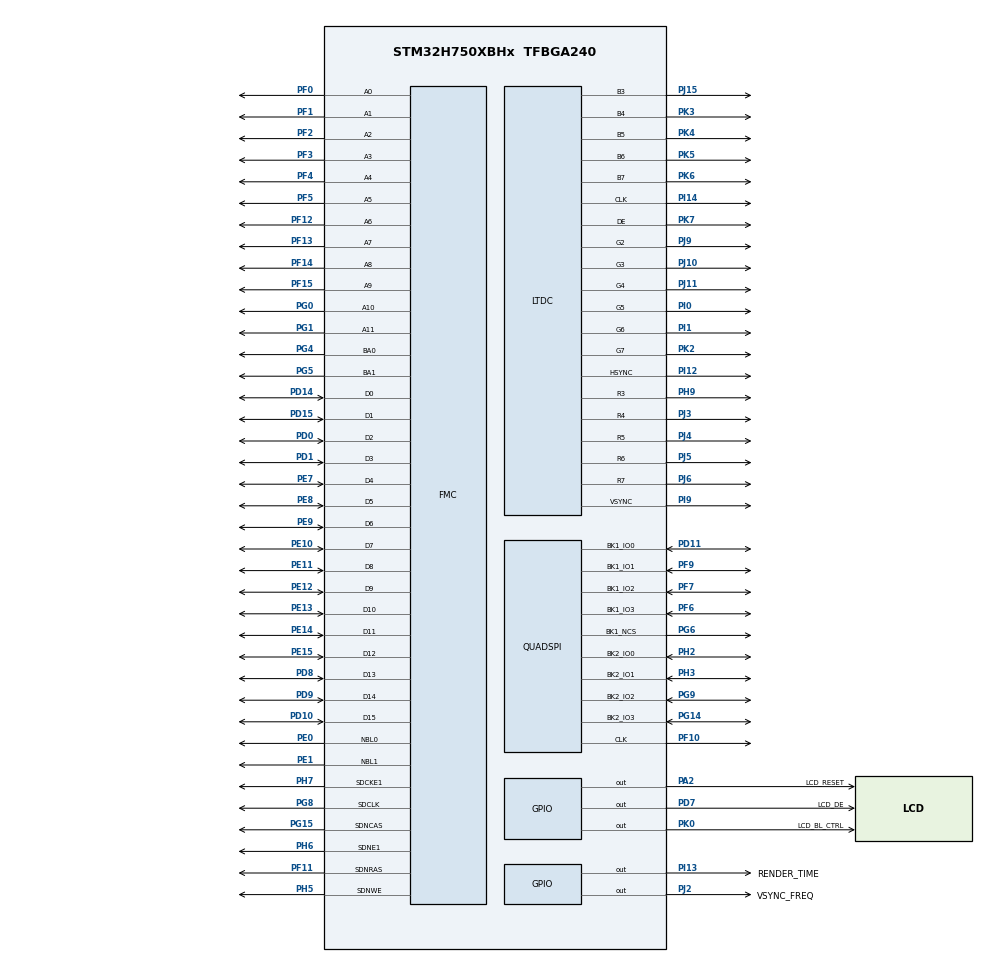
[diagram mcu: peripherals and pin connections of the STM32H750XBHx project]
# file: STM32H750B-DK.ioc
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SH.FMC_D7_DA7.0=FMC_D7,sd-16b-d2
PK5.Signal=LTDC_B6
VP_SYS_VS_tim6.Mode=TIM6
FMC.RCDDelay2=2
PJ9.Mode=RGB565
FMC.SDClockPeriod2=FMC_SDRAM_CLOCK_PERIOD_2
SH.FMC_A0.0=FMC_A0,12b-sda2
QUADSPI.ClockPrescaler=3
CORTEX_M7.BaseAddress-Cortex_Memory_Protection_Unit_Region3_Settings=0xD0000000
NVIC.TIM6_DAC_IRQn=true\:0\:0\:false\:false\:true\:false\:false\:true
PG8.Signal=FMC_SDCLK
PG4.Signal=FMC_A14_BA0
PJ10.GPIO_Speed=GPIO_SPEED_FREQ_HIGH
PG0.Signal=FMC_A10
FMC.LoadToActiveDelay2=2
CORTEX_M7.AccessPermission-Cortex_Memory_Protection_Unit_Region2_Settings=MPU_REGION_FULL_ACCESS
PJ8.GPIO_Speed=GPIO_SPEED_FREQ_HIGH
CORTEX_M7.IsShareable-Cortex_Memory_Protection_Unit_Region4_Settings=MPU_ACCESS_NOT_SHAREABLE
SH.FMC_D5_DA5.0=FMC_D5,sd-16b-d2
PG6.Mode=Enable Chip Select 1 for both banks
RCC.SYSCLKSource=RCC_SYSCLKSOURCE_PLLCLK
PJ10.Signal=LTDC_G3
SH.FMC_A15_BA1.0=FMC_BA1,FourSdramBanks2
SH.FMC_D9_DA9.0=FMC_D9,sd-16b-d2
CORTEX_M7.Enable-Cortex_Memory_Protection_Unit_Region0_Settings=MPU_REGION_ENABLE
CORTEX_M7.IsBufferable-Cortex_Memory_Protection_Unit_Region1_Settings=MPU_ACCESS_NOT_BUFFERABLE
PH5.Signal=FMC_SDNWE
PF7.Signal=QUADSPI_BK1_IO2
NVIC.DMA2D_IRQn=true\:5\:0\:true\:false\:true\:true\:true\:true
PI13.PinState=GPIO_PIN_SET
SH.FMC_SDNWE.0=FMC_SDNWE,12b-sda2
PH9.Signal=LTDC_R3
SH.FMC_D11_DA11.0=FMC_D11,sd-16b-d2
PJ5.Mode=RGB565
PD0.Signal=FMC_D2_DA2
PD8.Signal=FMC_D13_DA13
PE1.Signal=FMC_NBL1
QUADSPI.FlashSize=26
RCC.DIVM3=5
RCC.DIVM1=5
PG14.Mode=Dual_Bank
FMC.SelfRefreshTime2=4
LTDC.PixelFormat_L0=LTDC_PIXEL_FORMAT_RGB565
PK7.Mode=RGB565
PE9.Signal=FMC_D6_DA6
SH.FMC_A2.0=FMC_A2,12b-sda2
FREERTOS.HEAP_NUMBER=4
STMicroelectronics.X-CUBE-TOUCHGFX.4.16.1.tgfx_display_interface=disp_ltdc
PJ1.GPIO_Speed=GPIO_SPEED_FREQ_HIGH
SH.FMC_D1_DA1.0=FMC_D1,sd-16b-d2
PF3.Signal=FMC_A3
CORTEX_M7.Size-Cortex_Memory_Protection_Unit_Region4_Settings=MPU_REGION_SIZE_32MB
PE10.Signal=FMC_D7_DA7
LTDC.HSync=40
CORTEX_M7.DisableExec-Cortex_Memory_Protection_Unit_Region1_Settings=MPU_INSTRUCTION_ACCESS_DISABLE
PJ14.Signal=LTDC_B2
Mcu.Package=TFBGA240
NVIC.TimeBase=TIM6_DAC_IRQn
PH3.GPIO_Speed=GPIO_SPEED_FREQ_VERY_HIGH
RCC.PLL3FRACN=0
PK6.GPIO_Speed=GPIO_SPEED_FREQ_HIGH
STMicroelectronics.X-CUBE-TOUCHGFX.4.16.1.ApplicationCcGraphicsJjApplication=TouchGFXOoGenerator
PJ4.Signal=LTDC_R5
NVIC.TimeBaseIP=TIM6
CORTEX_M7.BaseAddress-Cortex_Memory_Protection_Unit_Region4_Settings=0xD0000000
FMC.WriteRecoveryTime2=5
SH.FMC_A1.0=FMC_A1,12b-sda2
PI12.GPIO_Speed=GPIO_SPEED_FREQ_HIGH
PH2.Signal=QUADSPI_BK2_IO0
PJ3.GPIO_Speed=GPIO_SPEED_FREQ_HIGH
SH.FMC_SDCLK.0=FMC_SDCLK,12b-sda2
LTDC.VSync=9
RCC.APB4Freq_Value=100000000
PF14.Signal=FMC_A8
CORTEX_M7.Enable-Cortex_Memory_Protection_Unit_Region1_Settings=MPU_REGION_ENABLE
VP_DMA2D_VS_DMA2D.Mode=DMA2D_Activate
FMC.RowCycleDelay2=7
PF10.Mode=Dual_Bank
FMC.ColumnBitsNumber2=FMC_SDRAM_COLUMN_BITS_NUM_8
PH0-OSC_IN\ (PH0).Mode=HSE-External-Oscillator
SH.FMC_D3_DA3.0=FMC_D3,sd-16b-d2
PD15.Signal=FMC_D1_DA1
CORTEX_M7.IsBufferable-Cortex_Memory_Protection_Unit_Region0_Settings=MPU_ACCESS_BUFFERABLE
PJ5.GPIO_Speed=GPIO_SPEED_FREQ_HIGH
PG6.GPIO_Speed=GPIO_SPEED_FREQ_VERY_HIGH
PI14.GPIO_Speed=GPIO_SPEED_FREQ_HIGH
VP_STMicroelectronics.X-CUBE-TOUCHGFX_VS_GraphicsJjApplication_4.16.1.Mode=GraphicsJjApplication
PK4.Signal=LTDC_B5
SH.FMC_A4.0=FMC_A4,12b-sda2
RCC.DIVQ1=4
FREERTOS.Tasks01=GUITask,24,8192,TouchGFX_Task,As weak,NULL,Dynamic,NULL,NULL
STMicroelectronics.X-CUBE-TOUCHGFX.4.16.1.tgfx_address1=0xD0000000
STMicroelectronics.X-CUBE-TOUCHGFX.4.16.1.tgfx_address2=0xD003FC00
PG5.Signal=FMC_A15_BA1
PG9.Signal=QUADSPI_BK2_IO2
SH.FMC_D10_DA10.0=FMC_D10,sd-16b-d2
CORTEX_M7.IsBufferable-Cortex_Memory_Protection_Unit_Region2_Settings=MPU_ACCESS_BUFFERABLE
CORTEX_M7.IsCacheable-Cortex_Memory_Protection_Unit_Region0_Settings=MPU_ACCESS_CACHEABLE
CORTEX_M7.Enable-Cortex_Memory_Protection_Unit_Region4_Settings=MPU_REGION_ENABLE
PG9.Mode=Dual_Bank
PD7.Signal=GPIO_Output
PD1.Signal=FMC_D3_DA3
PI12.Signal=LTDC_HSYNC
PJ11.Signal=LTDC_G4
LTDC.ImageWidth_L0=480
PD10.Signal=FMC_D15_DA15
PJ6.Mode=RGB565
SH.FMC_A3.0=FMC_A3,12b-sda2
PJ7.Signal=LTDC_G0
PJ3.Signal=LTDC_R4
FMC.CASLatency2=FMC_SDRAM_CAS_LATENCY_3
PI0.GPIO_Speed=GPIO_SPEED_FREQ_HIGH
SH.FMC_D15_DA15.0=FMC_D15,sd-16b-d2
PD11.GPIO_Speed=GPIO_SPEED_FREQ_VERY_HIGH
PH9.Mode=RGB565
RCC.DIVN3=160
RCC.DIVN1=160
CORTEX_M7.BaseAddress-Cortex_Memory_Protection_Unit_Region0_Settings=0x24000000
PJ13.GPIO_Speed=GPIO_SPEED_FREQ_HIGH
CORTEX_M7.Enable-Cortex_Memory_Protection_Unit_Region2_Settings=MPU_REGION_ENABLE
PJ15.Signal=LTDC_B3
PJ14.GPIO_Speed=GPIO_SPEED_FREQ_HIGH
PH6.Mode=SdramChipSelect2_2
SH.FMC_A6.0=FMC_A6,12b-sda2
PK0.PinState=GPIO_PIN_SET
FMC.ReadBurst2=FMC_SDRAM_RBURST_ENABLE
PE14.Signal=FMC_D11_DA11
PE15.Signal=FMC_D12_DA12
PE8.Signal=FMC_D5_DA5
PI1.Signal=LTDC_G6
CORTEX_M7.AccessPermission-Cortex_Memory_Protection_Unit_Region0_Settings=MPU_REGION_FULL_ACCESS
PF13.Signal=FMC_A7
SH.FMC_SDNCAS.0=FMC_SDNCAS,12b-sda2
PJ15.Mode=RGB565
PK4.Mode=RGB565
PD11.Signal=QUADSPI_BK1_IO0
SH.FMC_A5.0=FMC_A5,12b-sda2
LTDC.Alpha_L0=255
PJ6.GPIO_Speed=GPIO_SPEED_FREQ_HIGH
PJ8.Signal=LTDC_G1
ProjectManager.HeapSize=0x1000
PH6.Signal=FMC_SDNE1
PF6.Mode=Dual_Bank
PF9.Signal=QUADSPI_BK1_IO1
PJ10.Mode=RGB565
CORTEX_M7.DisableExec-Cortex_Memory_Protection_Unit_Region2_Settings=MPU_INSTRUCTION_ACCESS_ENABLE
NVIC.PriorityGroup=NVIC_PRIORITYGROUP_4
PJ4.Mode=RGB565
PF4.Signal=FMC_A4
RCC.DIVR3=83
PI13.GPIO_Speed=GPIO_SPEED_FREQ_VERY_HIGH
PF6.GPIO_Speed=GPIO_SPEED_FREQ_VERY_HIGH
PK5.GPIO_Speed=GPIO_SPEED_FREQ_HIGH
PI12.Mode=RGB565
STMicroelectronics.X-CUBE-TOUCHGFX.4.16.1.tgfx_pixel_format=RGB565\:16
Mcu.Family=STM32H7
QUADSPI.ClockMode=QSPI_CLOCK_MODE_0
PK7.Signal=LTDC_DE
LTDC.BlendingFactor1_L0=LTDC_BLENDING_FACTOR1_CA
PK3.Signal=LTDC_B4
SH.FMC_A8.0=FMC_A8,12b-sda2
CORTEX_M7.DisableExec-Cortex_Memory_Protection_Unit_Region4_Settings=MPU_INSTRUCTION_ACCESS_DISABLE
RCC.CortexFreq_Value=400000000
PK2.GPIO_Speed=GPIO_SPEED_FREQ_HIGH
PG6.Signal=QUADSPI_BK1_NCS
RCC.HPRE=RCC_HCLK_DIV2
SH.FMC_D14_DA14.0=FMC_D14,sd-16b-d2
PH0-OSC_IN\ (PH0).Signal=RCC_OSC_IN
LTDC.HBP=3
STMicroelectronics.X-CUBE-TOUCHGFX.4.16.1.tgfx_buffering_strategy=Double
SH.FMC_NBL0.0=FMC_NBL0,Sd2ByteEnable2
SH.FMC_D6_DA6.0=FMC_D6,sd-16b-d2
PF9.GPIO_Speed=GPIO_SPEED_FREQ_VERY_HIGH
SH.FMC_A14_BA0.0=FMC_BA0,FourSdramBanks2
PH9.GPIO_Speed=GPIO_SPEED_FREQ_HIGH
SH.FMC_A11.0=FMC_A11,12b-sda2
PG9.GPIO_Speed=GPIO_SPEED_FREQ_VERY_HIGH
PI9.GPIO_Speed=GPIO_SPEED_FREQ_HIGH
PH2.GPIO_Speed=GPIO_SPEED_FREQ_VERY_HIGH
PJ2.GPIO_Speed=GPIO_SPEED_FREQ_VERY_HIGH
STMicroelectronics.X-CUBE-TOUCHGFX.4.16.1.tgfx_location=By Address
PJ9.GPIO_Speed=GPIO_SPEED_FREQ_HIGH
PG15.Signal=FMC_SDNCAS
ProjectManager.StackSize=0x1000
VP_FREERTOS_VS_CMSIS_V2.Mode=CMSIS_V2
PH3.Mode=Dual_Bank
CORTEX_M7.IsShareable-Cortex_Memory_Protection_Unit_Region2_Settings=MPU_ACCESS_NOT_SHAREABLE
PJ6.Signal=LTDC_R7
PJ11.GPIO_Speed=GPIO_SPEED_FREQ_HIGH
SH.FMC_A7.0=FMC_A7,12b-sda2
PJ2.Signal=GPIO_Output
RCC.HCLKFreq_Value=200000000
PJ2.PinState=GPIO_PIN_SET
SH.FMC_NBL1.0=FMC_NBL1,Sd2ByteEnable2
LTDC.WindowX1_L0=480
PF12.Signal=FMC_A6
PI9.Mode=RGB565
FREERTOS.configUSE_MALLOC_FAILED_HOOK=0
PK2.Mode=RGB565
PI13.Signal=GPIO_Output
SH.FMC_A10.0=FMC_A10,12b-sda2
PH1-OSC_OUT\ (PH1).Mode=HSE-External-Oscillator
SH.FMC_D8_DA8.0=FMC_D8,sd-16b-d2
CORTEX_M7.Size-Cortex_Memory_Protection_Unit_Region2_Settings=MPU_REGION_SIZE_128MB
FMC.RPDelay2=2
FMC.ExitSelfRefreshDelay2=7
PI14.Mode=RGB565
SH.FMC_D2_DA2.0=FMC_D2,sd-16b-d2
LTDC.VBP=3
PI13.GPIO_PuPd=GPIO_PULLUP
CORTEX_M7.IsCacheable-Cortex_Memory_Protection_Unit_Region2_Settings=MPU_ACCESS_CACHEABLE
PF9.Mode=Dual_Bank
PE13.Signal=FMC_D10_DA10
PF7.GPIO_Speed=GPIO_SPEED_FREQ_VERY_HIGH
PK6.Mode=RGB565
PI0.Signal=LTDC_G5
PF11.Signal=FMC_SDNRAS
PJ7.GPIO_Speed=GPIO_SPEED_FREQ_HIGH
LTDC.BlendingFactor2_L0=LTDC_BLENDING_FACTOR2_CA
SH.FMC_SDNRAS.0=FMC_SDNRAS,12b-sda2
DMA2D.ColorMode=DMA2D_OUTPUT_RGB565
LTDC.ActiveW=480
QUADSPI.SampleShifting=QSPI_SAMPLE_SHIFTING_NONE
CORTEX_M7.DisableExec-Cortex_Memory_Protection_Unit_Region0_Settings=MPU_INSTRUCTION_ACCESS_DISABLE
FREERTOS.configTOTAL_HEAP_SIZE=65536
PD7.GPIO_Label=LCD_DE
PH7.Mode=SdramChipSelect2_2
RCC.APB3Freq_Value=100000000
PJ9.Signal=LTDC_G2
SH.FMC_D0_DA0.0=FMC_D0,sd-16b-d2
RCC.D1PPRE=RCC_APB3_DIV2
PJ12.Signal=LTDC_B0
CORTEX_M7.BaseAddress-Cortex_Memory_Protection_Unit_Region1_Settings=0x90000000
PK0.GPIO_Label=LCD_BL_CTRL
PA2.GPIO_Label=LCD_RESET
SH.FMC_A9.0=FMC_A9,12b-sda2
PJ1.Signal=LTDC_R2
SH.FMC_D4_DA4.0=FMC_D4,sd-16b-d2
PI1.Mode=RGB565
PF5.Signal=FMC_A5
CORTEX_M7.Size-Cortex_Memory_Protection_Unit_Region1_Settings=MPU_REGION_SIZE_256MB
PH7.Signal=FMC_SDCKE1
PF0.Signal=FMC_A0
PK4.GPIO_Speed=GPIO_SPEED_FREQ_HIGH
PH2.Mode=Dual_Bank
PE7.Signal=FMC_D4_DA4
STMicroelectronics.X-CUBE-TOUCHGFX.4.16.1.tgfx_vsync=vsync_ltdc
RCC.PLLSourceVirtual=RCC_PLLSOURCE_HSE
PK6.Signal=LTDC_B7
QUADSPI.ChipSelectHighTime=QSPI_CS_HIGH_TIME_4_CYCLE
NVIC.LTDC_IRQn=true\:5\:0\:true\:false\:true\:true\:true\:true
PK2.Signal=LTDC_G7
CORTEX_M7.CPU_ICache=Enabled
LTDC.WindowY1_L0=272
PG1.Signal=FMC_A11
PI14.Signal=LTDC_CLK
PF10.GPIO_Speed=GPIO_SPEED_FREQ_VERY_HIGH
RCC.D2PPRE2=RCC_APB2_DIV2
PJ2.GPIO_PuPd=GPIO_PULLUP
RCC.D2PPRE1=RCC_APB1_DIV2
PD9.Signal=FMC_D14_DA14
FREERTOS.configUSE_APPLICATION_TASK_TAG=1
CORTEX_M7.BaseAddress-Cortex_Memory_Protection_Unit_Region2_Settings=0x90000000
PH1-OSC_OUT\ (PH1).Signal=RCC_OSC_OUT
PJ11.Mode=RGB565
FREERTOS.configUSE_IDLE_HOOK=1
PF7.Mode=Dual_Bank
CORTEX_M7.MPU_Control=MPU_PRIVILEGED_DEFAULT
PF6.Signal=QUADSPI_BK1_IO3
PJ0.GPIO_Speed=GPIO_SPEED_FREQ_HIGH
STMicroelectronics.X-CUBE-TOUCHGFX.4.16.1.tgfx_hardware_accelerator=dma_2d
ProjectManager.TargetToolchain=STM32CubeIDE
SH.FMC_D13_DA13.0=FMC_D13,sd-16b-d2
LTDC.ActiveH=272
PI0.Mode=RGB565
CORTEX_M7.DisableExec-Cortex_Memory_Protection_Unit_Region3_Settings=MPU_INSTRUCTION_ACCESS_DISABLE
PF2.Signal=FMC_A2
RCC.USBFreq_Value=200000000
PE11.Signal=FMC_D8_DA8
PK0.Signal=GPIO_Output
PK5.Mode=RGB565
PG14.Signal=QUADSPI_BK2_IO3
board=custom
PJ15.GPIO_Speed=GPIO_SPEED_FREQ_HIGH
PI9.Signal=LTDC_VSYNC
PJ3.Mode=RGB565
PI13.GPIO_Label=RENDER_TIME
RCC.APB2Freq_Value=100000000
LTDC.Layers=1
PK7.GPIO_Speed=GPIO_SPEED_FREQ_HIGH
PF10.Signal=QUADSPI_CLK
RCC.ADCFreq_Value=50390625
PJ12.GPIO_Speed=GPIO_SPEED_FREQ_HIGH
SH.FMC_D12_DA12.0=FMC_D12,sd-16b-d2
PF15.Signal=FMC_A9
PF1.Signal=FMC_A1
PI1.GPIO_Speed=GPIO_SPEED_FREQ_HIGH
PJ0.Signal=LTDC_R1
Mcu.Name=STM32H750XBHx
PE0.Signal=FMC_NBL0
CORTEX_M7.Size-Cortex_Memory_Protection_Unit_Region0_Settings=MPU_REGION_SIZE_512KB
PE12.Signal=FMC_D9_DA9
PA2.Signal=GPIO_Output
CORTEX_M7.AccessPermission-Cortex_Memory_Protection_Unit_Region1_Settings=MPU_REGION_NO_ACCESS
CORTEX_M7.IsCacheable-Cortex_Memory_Protection_Unit_Region1_Settings=MPU_ACCESS_NOT_CACHEABLE
PD14.Signal=FMC_D0_DA0
RCC.SYSCLKFreq_VALUE=400000000
PI15.GPIO_Speed=GPIO_SPEED_FREQ_HIGH
PJ5.Signal=LTDC_R6
PD11.Mode=Dual_Bank
CORTEX_M7.Enable-Cortex_Memory_Protection_Unit_Region3_Settings=MPU_REGION_ENABLE
CORTEX_M7.Size-Cortex_Memory_Protection_Unit_Region3_Settings=MPU_REGION_SIZE_256MB
PK3.Mode=RGB565
PH3.Signal=QUADSPI_BK2_IO1
PK3.GPIO_Speed=GPIO_SPEED_FREQ_HIGH
PI15.Signal=LTDC_R0
RCC.D3PPRE=RCC_APB4_DIV2
CORTEX_M7.CPU_DCache=Enabled
PJ4.GPIO_Speed=GPIO_SPEED_FREQ_HIGH
RCC.APB1Freq_Value=100000000
PJ2.GPIO_Label=VSYNC_FREQ
PG14.GPIO_Speed=GPIO_SPEED_FREQ_VERY_HIGH
VP_CRC_VS_CRC.Mode=CRC_Activate
LTDC.ImageHeight_L0=272
CORTEX_M7.AccessPermission-Cortex_Memory_Protection_Unit_Region4_Settings=MPU_REGION_FULL_ACCESS
PJ13.Signal=LTDC_B1
CORTEX_M7.IsCacheable-Cortex_Memory_Protection_Unit_Region4_Settings=MPU_ACCESS_CACHEABLE

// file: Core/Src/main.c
/* USER CODE BEGIN Header */
/**
  ******************************************************************************
  * @file           : main.c
  * @brief          : Main program body
  ******************************************************************************
  * @attention
  *
  * <h2><center>&copy; Copyright (c) 2020 STMicroelectronics.
  * All rights reserved.</center></h2>
  *
  * This software component is licensed by ST under Ultimate Liberty license
  * SLA0044, the "License"; You may not use this file except in compliance with
  * the License. You may obtain a copy of the License at:
  *                             www.st.com/SLA0044
  *
  ******************************************************************************
  */
/* USER CODE END Header */
#include "main.h"
#include "cmsis_os.h"
#include "app_touchgfx.h"

/* USER CODE BEGIN Includes */
#include "stm32h750b_discovery_qspi.h"
#include "stm32h750b_discovery_sdram.h"
/* USER CODE END Includes */

CRC_HandleTypeDef hcrc;

DMA2D_HandleTypeDef hdma2d;

LTDC_HandleTypeDef hltdc;

QSPI_HandleTypeDef hqspi;

SDRAM_HandleTypeDef hsdram2;

/* Definitions for GUITask */
osThreadId_t GUITaskHandle;
const osThreadAttr_t GUITask_attributes = {
  .name = "GUITask",
  .priority = (osPriority_t) osPriorityNormal,
  .stack_size = 8192 * 4
};

void SystemClock_Config(void);
static void MPU_Config(void);
static void MX_GPIO_Init(void);
static void MX_CRC_Init(void);
static void MX_LTDC_Init(void);
static void MX_DMA2D_Init(void);
static void MX_QUADSPI_Init(void);
static void MX_FMC_Init(void);
void TouchGFX_Task(void *argument);

int main(void)
{

  /* MPU Configuration--------------------------------------------------------*/
  MPU_Config();

  /* Enable I-Cache---------------------------------------------------------*/
  SCB_EnableICache();

  /* Enable D-Cache------------------------------------------------    ---------*/
  SCB_EnableDCache();

  /* MCU Configuration--------------------------------------------------------*/

  /* Reset of all peripherals, Initializes the Flash interface and the Systick. */
  HAL_Init();

  /* Configure the system clock */
  SystemClock_Config();

  /* USER CODE BEGIN SysInit */
  /* Explicit enabling interrupt to support debugging in CubeIDE when using external flash loader */
  __enable_irq();
  /* USER CODE END SysInit */

  /* Initialize all configured peripherals */
  MX_GPIO_Init();
  MX_CRC_Init();
  MX_LTDC_Init();
  MX_DMA2D_Init();
  MX_FMC_Init();
  MX_TouchGFX_Init();

  /* Init scheduler */
  osKernelInitialize();

  /* Create the thread(s) */
  /* creation of GUITask */
  GUITaskHandle = osThreadNew(TouchGFX_Task, NULL, &GUITask_attributes);

  /* Start scheduler */
  osKernelStart();

  /* We should never get here as control is now taken by the scheduler */
  /* Infinite loop */
  while (1)
  {

  }
}

void SystemClock_Config(void)
{
  RCC_OscInitTypeDef RCC_OscInitStruct = {0};
  RCC_ClkInitTypeDef RCC_ClkInitStruct = {0};
  RCC_PeriphCLKInitTypeDef PeriphClkInitStruct = {0};

  /** Supply configuration update enable
  */
  HAL_PWREx_ConfigSupply(PWR_LDO_SUPPLY);
  /** Configure the main internal regulator output voltage
  */
  __HAL_PWR_VOLTAGESCALING_CONFIG(PWR_REGULATOR_VOLTAGE_SCALE1);

  while(!__HAL_PWR_GET_FLAG(PWR_FLAG_VOSRDY)) {}
  /** Macro to configure the PLL clock source
  */
  __HAL_RCC_PLL_PLLSOURCE_CONFIG(RCC_PLLSOURCE_HSE);
  /** Initializes the RCC Oscillators according to the specified parameters
  * in the RCC_OscInitTypeDef structure.
  */
  RCC_OscInitStruct.OscillatorType = RCC_OSCILLATORTYPE_HSE;
  RCC_OscInitStruct.HSEState = RCC_HSE_ON;
  RCC_OscInitStruct.PLL.PLLState = RCC_PLL_ON;
  RCC_OscInitStruct.PLL.PLLSource = RCC_PLLSOURCE_HSE;
  RCC_OscInitStruct.PLL.PLLM = 5;
  RCC_OscInitStruct.PLL.PLLN = 160;
  RCC_OscInitStruct.PLL.PLLP = 2;
  RCC_OscInitStruct.PLL.PLLQ = 4;
  RCC_OscInitStruct.PLL.PLLR = 2;
  RCC_OscInitStruct.PLL.PLLRGE = RCC_PLL1VCIRANGE_2;
  RCC_OscInitStruct.PLL.PLLVCOSEL = RCC_PLL1VCOWIDE;
  RCC_OscInitStruct.PLL.PLLFRACN = 0;
  if (HAL_RCC_OscConfig(&RCC_OscInitStruct) != HAL_OK)
  {
    Error_Handler();
  }
  /** Initializes the CPU, AHB and APB buses clocks
  */
  RCC_ClkInitStruct.ClockType = RCC_CLOCKTYPE_HCLK|RCC_CLOCKTYPE_SYSCLK
                              |RCC_CLOCKTYPE_PCLK1|RCC_CLOCKTYPE_PCLK2
                              |RCC_CLOCKTYPE_D3PCLK1|RCC_CLOCKTYPE_D1PCLK1;
  RCC_ClkInitStruct.SYSCLKSource = RCC_SYSCLKSOURCE_PLLCLK;
  RCC_ClkInitStruct.SYSCLKDivider = RCC_SYSCLK_DIV1;
  RCC_ClkInitStruct.AHBCLKDivider = RCC_HCLK_DIV2;
  RCC_ClkInitStruct.APB3CLKDivider = RCC_APB3_DIV2;
  RCC_ClkInitStruct.APB1CLKDivider = RCC_APB1_DIV2;
  RCC_ClkInitStruct.APB2CLKDivider = RCC_APB2_DIV2;
  RCC_ClkInitStruct.APB4CLKDivider = RCC_APB4_DIV2;

  if (HAL_RCC_ClockConfig(&RCC_ClkInitStruct, FLASH_LATENCY_2) != HAL_OK)
  {
    Error_Handler();
  }
  PeriphClkInitStruct.PeriphClockSelection = RCC_PERIPHCLK_LTDC|RCC_PERIPHCLK_QSPI
                              |RCC_PERIPHCLK_FMC;
  PeriphClkInitStruct.PLL3.PLL3M = 5;
  PeriphClkInitStruct.PLL3.PLL3N = 160;
  PeriphClkInitStruct.PLL3.PLL3P = 2;
  PeriphClkInitStruct.PLL3.PLL3Q = 2;
  PeriphClkInitStruct.PLL3.PLL3R = 83;
  PeriphClkInitStruct.PLL3.PLL3RGE = RCC_PLL3VCIRANGE_2;
  PeriphClkInitStruct.PLL3.PLL3VCOSEL = RCC_PLL3VCOWIDE;
  PeriphClkInitStruct.PLL3.PLL3FRACN = 0;
  PeriphClkInitStruct.FmcClockSelection = RCC_FMCCLKSOURCE_D1HCLK;
  PeriphClkInitStruct.QspiClockSelection = RCC_QSPICLKSOURCE_D1HCLK;
  if (HAL_RCCEx_PeriphCLKConfig(&PeriphClkInitStruct) != HAL_OK)
  {
    Error_Handler();
  }
}

static void MX_CRC_Init(void)
{

  hcrc.Instance = CRC;
  hcrc.Init.DefaultPolynomialUse = DEFAULT_POLYNOMIAL_ENABLE;
  hcrc.Init.DefaultInitValueUse = DEFAULT_INIT_VALUE_ENABLE;
  hcrc.Init.InputDataInversionMode = CRC_INPUTDATA_INVERSION_NONE;
  hcrc.Init.OutputDataInversionMode = CRC_OUTPUTDATA_INVERSION_DISABLE;
  hcrc.InputDataFormat = CRC_INPUTDATA_FORMAT_BYTES;
  if (HAL_CRC_Init(&hcrc) != HAL_OK)
  {
    Error_Handler();
  }

}

static void MX_DMA2D_Init(void)
{

  hdma2d.Instance = DMA2D;
  hdma2d.Init.Mode = DMA2D_M2M;
  hdma2d.Init.ColorMode = DMA2D_OUTPUT_RGB565;
  hdma2d.Init.OutputOffset = 0;
  hdma2d.Init.BytesSwap = DMA2D_BYTES_REGULAR;
  hdma2d.Init.LineOffsetMode = DMA2D_LOM_PIXELS;
  hdma2d.LayerCfg[1].InputOffset = 0;
  hdma2d.LayerCfg[1].InputColorMode = DMA2D_INPUT_RGB565;
  hdma2d.LayerCfg[1].AlphaMode = DMA2D_NO_MODIF_ALPHA;
  hdma2d.LayerCfg[1].InputAlpha = 0;
  hdma2d.LayerCfg[1].AlphaInverted = DMA2D_REGULAR_ALPHA;
  hdma2d.LayerCfg[1].RedBlueSwap = DMA2D_RB_REGULAR;
  hdma2d.LayerCfg[1].ChromaSubSampling = DMA2D_NO_CSS;
  if (HAL_DMA2D_Init(&hdma2d) != HAL_OK)
  {
    Error_Handler();
  }
  if (HAL_DMA2D_ConfigLayer(&hdma2d, 1) != HAL_OK)
  {
    Error_Handler();
  }

}

static void MX_LTDC_Init(void)
{

  LTDC_LayerCfgTypeDef pLayerCfg = {0};
  LTDC_LayerCfgTypeDef pLayerCfg1 = {0};

  hltdc.Instance = LTDC;
  hltdc.Init.HSPolarity = LTDC_HSPOLARITY_AL;
  hltdc.Init.VSPolarity = LTDC_VSPOLARITY_AL;
  hltdc.Init.DEPolarity = LTDC_DEPOLARITY_AL;
  hltdc.Init.PCPolarity = LTDC_PCPOLARITY_IPC;
  hltdc.Init.HorizontalSync = 39;
  hltdc.Init.VerticalSync = 8;
  hltdc.Init.AccumulatedHBP = 42;
  hltdc.Init.AccumulatedVBP = 11;
  hltdc.Init.AccumulatedActiveW = 522;
  hltdc.Init.AccumulatedActiveH = 283;
  hltdc.Init.TotalWidth = 528;
  hltdc.Init.TotalHeigh = 285;
  hltdc.Init.Backcolor.Blue = 0;
  hltdc.Init.Backcolor.Green = 0;
  hltdc.Init.Backcolor.Red = 0;
  if (HAL_LTDC_Init(&hltdc) != HAL_OK)
  {
    Error_Handler();
  }
  pLayerCfg.WindowX0 = 0;
  pLayerCfg.WindowX1 = 480;
  pLayerCfg.WindowY0 = 0;
  pLayerCfg.WindowY1 = 272;
  pLayerCfg.PixelFormat = LTDC_PIXEL_FORMAT_RGB565;
  pLayerCfg.Alpha = 255;
  pLayerCfg.Alpha0 = 0;
  pLayerCfg.BlendingFactor1 = LTDC_BLENDING_FACTOR1_CA;
  pLayerCfg.BlendingFactor2 = LTDC_BLENDING_FACTOR2_CA;
  pLayerCfg.FBStartAdress = 0;
  pLayerCfg.ImageWidth = 480;
  pLayerCfg.ImageHeight = 272;
  pLayerCfg.Backcolor.Blue = 0;
  pLayerCfg.Backcolor.Green = 0;
  pLayerCfg.Backcolor.Red = 0;
  if (HAL_LTDC_ConfigLayer(&hltdc, &pLayerCfg, 0) != HAL_OK)
  {
    Error_Handler();
  }
  pLayerCfg1.WindowX0 = 0;
  pLayerCfg1.WindowX1 = 0;
  pLayerCfg1.WindowY0 = 0;
  pLayerCfg1.WindowY1 = 0;
  pLayerCfg1.PixelFormat = LTDC_PIXEL_FORMAT_ARGB8888;
  pLayerCfg1.Alpha = 0;
  pLayerCfg1.Alpha0 = 0;
  pLayerCfg1.BlendingFactor1 = LTDC_BLENDING_FACTOR1_CA;
  pLayerCfg1.BlendingFactor2 = LTDC_BLENDING_FACTOR2_CA;
  pLayerCfg1.FBStartAdress = 0;
  pLayerCfg1.ImageWidth = 0;
  pLayerCfg1.ImageHeight = 0;
  pLayerCfg1.Backcolor.Blue = 0;
  pLayerCfg1.Backcolor.Green = 0;
  pLayerCfg1.Backcolor.Red = 0;
  if (HAL_LTDC_ConfigLayer(&hltdc, &pLayerCfg1, 1) != HAL_OK)
  {
    Error_Handler();
  }

}

static void MX_QUADSPI_Init(void)
{

  /* USER CODE BEGIN QUADSPI_Init 0 */
  BSP_QSPI_Init_t qspi_initParams ;
  /* USER CODE END QUADSPI_Init 0 */

  /* QUADSPI parameter configuration*/
  hqspi.Instance = QUADSPI;
  hqspi.Init.ClockPrescaler = 3;
  hqspi.Init.FifoThreshold = 1;
  hqspi.Init.SampleShifting = QSPI_SAMPLE_SHIFTING_NONE;
  hqspi.Init.FlashSize = 26;
  hqspi.Init.ChipSelectHighTime = QSPI_CS_HIGH_TIME_4_CYCLE;
  hqspi.Init.ClockMode = QSPI_CLOCK_MODE_0;
  hqspi.Init.DualFlash = QSPI_DUALFLASH_ENABLE;
  if (HAL_QSPI_Init(&hqspi) != HAL_OK)
  {
    Error_Handler();
  }
  /* USER CODE BEGIN QUADSPI_Init 2 */
  qspi_initParams.InterfaceMode = MT25TL01G_QPI_MODE;
  qspi_initParams.TransferRate  = MT25TL01G_DTR_TRANSFER ;
  qspi_initParams.DualFlashMode = MT25TL01G_DUALFLASH_ENABLE;
  BSP_QSPI_DeInit(0);
  if (BSP_QSPI_Init(0, &qspi_initParams) != BSP_ERROR_NONE)
  {
    Error_Handler( );
  }
  if(BSP_QSPI_EnableMemoryMappedMode(0) != BSP_ERROR_NONE)
  {
    Error_Handler( );
  }
  /* USER CODE END QUADSPI_Init 2 */

}

/* FMC initialization function */
static void MX_FMC_Init(void)
{

  FMC_SDRAM_TimingTypeDef SdramTiming = {0};

  /** Perform the SDRAM2 memory initialization sequence
  */
  hsdram2.Instance = FMC_SDRAM_DEVICE;
  /* hsdram2.Init */
  hsdram2.Init.SDBank = FMC_SDRAM_BANK2;
  hsdram2.Init.ColumnBitsNumber = FMC_SDRAM_COLUMN_BITS_NUM_8;
  hsdram2.Init.RowBitsNumber = FMC_SDRAM_ROW_BITS_NUM_12;
  hsdram2.Init.MemoryDataWidth = FMC_SDRAM_MEM_BUS_WIDTH_16;
  hsdram2.Init.InternalBankNumber = FMC_SDRAM_INTERN_BANKS_NUM_4;
  hsdram2.Init.CASLatency = FMC_SDRAM_CAS_LATENCY_3;
  hsdram2.Init.WriteProtection = FMC_SDRAM_WRITE_PROTECTION_DISABLE;
  hsdram2.Init.SDClockPeriod = FMC_SDRAM_CLOCK_PERIOD_2;
  hsdram2.Init.ReadBurst = FMC_SDRAM_RBURST_ENABLE;
  hsdram2.Init.ReadPipeDelay = FMC_SDRAM_RPIPE_DELAY_0;
  /* SdramTiming */
  SdramTiming.LoadToActiveDelay = 2;
  SdramTiming.ExitSelfRefreshDelay = 7;
  SdramTiming.SelfRefreshTime = 4;
  SdramTiming.RowCycleDelay = 7;
  SdramTiming.WriteRecoveryTime = 5;
  SdramTiming.RPDelay = 2;
  SdramTiming.RCDDelay = 2;

  if (HAL_SDRAM_Init(&hsdram2, &SdramTiming) != HAL_OK)
  {
    Error_Handler( );
  }

  /* USER CODE BEGIN FMC_Init 2 */
  BSP_SDRAM_DeInit(0);
  if(BSP_SDRAM_Init(0) != BSP_ERROR_NONE)
  {
    Error_Handler( );
  }
  /* USER CODE END FMC_Init 2 */
}

static void MX_GPIO_Init(void)
{
  GPIO_InitTypeDef GPIO_InitStruct = {0};

  /* GPIO Ports Clock Enable */
  __HAL_RCC_GPIOK_CLK_ENABLE();
  __HAL_RCC_GPIOG_CLK_ENABLE();
  __HAL_RCC_GPIOI_CLK_ENABLE();
  __HAL_RCC_GPIOE_CLK_ENABLE();
  __HAL_RCC_GPIOJ_CLK_ENABLE();
  __HAL_RCC_GPIOD_CLK_ENABLE();
  __HAL_RCC_GPIOF_CLK_ENABLE();
  __HAL_RCC_GPIOH_CLK_ENABLE();
  __HAL_RCC_GPIOA_CLK_ENABLE();

  /*Configure GPIO pin Output Level */
  HAL_GPIO_WritePin(LCD_DE_GPIO_Port, LCD_DE_Pin, GPIO_PIN_RESET);

  /*Configure GPIO pin Output Level */
  HAL_GPIO_WritePin(RENDER_TIME_GPIO_Port, RENDER_TIME_Pin, GPIO_PIN_SET);

  /*Configure GPIO pin Output Level */
  HAL_GPIO_WritePin(LCD_BL_CTRL_GPIO_Port, LCD_BL_CTRL_Pin, GPIO_PIN_SET);

  /*Configure GPIO pin Output Level */
  HAL_GPIO_WritePin(LCD_RESET_GPIO_Port, LCD_RESET_Pin, GPIO_PIN_RESET);

  /*Configure GPIO pin Output Level */
  HAL_GPIO_WritePin(VSYNC_FREQ_GPIO_Port, VSYNC_FREQ_Pin, GPIO_PIN_SET);

  /*Configure GPIO pin : LCD_DE_Pin */
  GPIO_InitStruct.Pin = LCD_DE_Pin;
  GPIO_InitStruct.Mode = GPIO_MODE_OUTPUT_PP;
  GPIO_InitStruct.Pull = GPIO_NOPULL;
  GPIO_InitStruct.Speed = GPIO_SPEED_FREQ_LOW;
  HAL_GPIO_Init(LCD_DE_GPIO_Port, &GPIO_InitStruct);

  /*Configure GPIO pin : RENDER_TIME_Pin */
  GPIO_InitStruct.Pin = RENDER_TIME_Pin;
  GPIO_InitStruct.Mode = GPIO_MODE_OUTPUT_PP;
  GPIO_InitStruct.Pull = GPIO_PULLUP;
  GPIO_InitStruct.Speed = GPIO_SPEED_FREQ_VERY_HIGH;
  HAL_GPIO_Init(RENDER_TIME_GPIO_Port, &GPIO_InitStruct);

  /*Configure GPIO pin : LCD_BL_CTRL_Pin */
  GPIO_InitStruct.Pin = LCD_BL_CTRL_Pin;
  GPIO_InitStruct.Mode = GPIO_MODE_OUTPUT_PP;
  GPIO_InitStruct.Pull = GPIO_NOPULL;
  GPIO_InitStruct.Speed = GPIO_SPEED_FREQ_LOW;
  HAL_GPIO_Init(LCD_BL_CTRL_GPIO_Port, &GPIO_InitStruct);

  /*Configure GPIO pin : LCD_RESET_Pin */
  GPIO_InitStruct.Pin = LCD_RESET_Pin;
  GPIO_InitStruct.Mode = GPIO_MODE_OUTPUT_PP;
  GPIO_InitStruct.Pull = GPIO_NOPULL;
  GPIO_InitStruct.Speed = GPIO_SPEED_FREQ_LOW;
  HAL_GPIO_Init(LCD_RESET_GPIO_Port, &GPIO_InitStruct);

  /*Configure GPIO pin : VSYNC_FREQ_Pin */
  GPIO_InitStruct.Pin = VSYNC_FREQ_Pin;
  GPIO_InitStruct.Mode = GPIO_MODE_OUTPUT_PP;
  GPIO_InitStruct.Pull = GPIO_PULLUP;
  GPIO_InitStruct.Speed = GPIO_SPEED_FREQ_VERY_HIGH;
  HAL_GPIO_Init(VSYNC_FREQ_GPIO_Port, &GPIO_InitStruct);

}

__weak void TouchGFX_Task(void *argument)
{
  for(;;)
  {
    osDelay(1);
  }
}

/* MPU Configuration */

void MPU_Config(void)
{
  MPU_Region_InitTypeDef MPU_InitStruct = {0};

  /* Disables the MPU */
  HAL_MPU_Disable();
  /** Initializes and configures the Region and the memory to be protected
  */
  MPU_InitStruct.Enable = MPU_REGION_ENABLE;
  MPU_InitStruct.Number = MPU_REGION_NUMBER0;
  MPU_InitStruct.BaseAddress = 0x24000000;
  MPU_InitStruct.Size = MPU_REGION_SIZE_512KB;
  MPU_InitStruct.SubRegionDisable = 0x0;
  MPU_InitStruct.TypeExtField = MPU_TEX_LEVEL0;
  MPU_InitStruct.AccessPermission = MPU_REGION_FULL_ACCESS;
  MPU_InitStruct.DisableExec = MPU_INSTRUCTION_ACCESS_DISABLE;
  MPU_InitStruct.IsShareable = MPU_ACCESS_NOT_SHAREABLE;
  MPU_InitStruct.IsCacheable = MPU_ACCESS_CACHEABLE;
  MPU_InitStruct.IsBufferable = MPU_ACCESS_BUFFERABLE;

  HAL_MPU_ConfigRegion(&MPU_InitStruct);
  /** Initializes and configures the Region and the memory to be protected
  */
  MPU_InitStruct.Enable = MPU_REGION_ENABLE;
  MPU_InitStruct.Number = MPU_REGION_NUMBER1;
  MPU_InitStruct.BaseAddress = 0x90000000;
  MPU_InitStruct.Size = MPU_REGION_SIZE_256MB;
  MPU_InitStruct.SubRegionDisable = 0x0;
  MPU_InitStruct.TypeExtField = MPU_TEX_LEVEL0;
  MPU_InitStruct.AccessPermission = MPU_REGION_NO_ACCESS;
  MPU_InitStruct.DisableExec = MPU_INSTRUCTION_ACCESS_DISABLE;
  MPU_InitStruct.IsShareable = MPU_ACCESS_NOT_SHAREABLE;
  MPU_InitStruct.IsCacheable = MPU_ACCESS_NOT_CACHEABLE;
  MPU_InitStruct.IsBufferable = MPU_ACCESS_NOT_BUFFERABLE;

  HAL_MPU_ConfigRegion(&MPU_InitStruct);
  /** Initializes and configures the Region and the memory to be protected
  */
  MPU_InitStruct.Enable = MPU_REGION_ENABLE;
  MPU_InitStruct.Number = MPU_REGION_NUMBER2;
  MPU_InitStruct.BaseAddress = 0x90000000;
  MPU_InitStruct.Size = MPU_REGION_SIZE_128MB;
  MPU_InitStruct.SubRegionDisable = 0x0;
  MPU_InitStruct.TypeExtField = MPU_TEX_LEVEL0;
  MPU_InitStruct.AccessPermission = MPU_REGION_FULL_ACCESS;
  MPU_InitStruct.DisableExec = MPU_INSTRUCTION_ACCESS_ENABLE;
  MPU_InitStruct.IsShareable = MPU_ACCESS_NOT_SHAREABLE;
  MPU_InitStruct.IsCacheable = MPU_ACCESS_CACHEABLE;
  MPU_InitStruct.IsBufferable = MPU_ACCESS_BUFFERABLE;

  HAL_MPU_ConfigRegion(&MPU_InitStruct);
  /** Initializes and configures the Region and the memory to be protected
  */
  MPU_InitStruct.Enable = MPU_REGION_ENABLE;
  MPU_InitStruct.Number = MPU_REGION_NUMBER3;
  MPU_InitStruct.BaseAddress = 0xD0000000;
  MPU_InitStruct.Size = MPU_REGION_SIZE_256MB;
  MPU_InitStruct.SubRegionDisable = 0x0;
  MPU_InitStruct.TypeExtField = MPU_TEX_LEVEL0;
  MPU_InitStruct.AccessPermission = MPU_REGION_NO_ACCESS;
  MPU_InitStruct.DisableExec = MPU_INSTRUCTION_ACCESS_DISABLE;
  MPU_InitStruct.IsShareable = MPU_ACCESS_NOT_SHAREABLE;
  MPU_InitStruct.IsCacheable = MPU_ACCESS_NOT_CACHEABLE;
  MPU_InitStruct.IsBufferable = MPU_ACCESS_NOT_BUFFERABLE;

  HAL_MPU_ConfigRegion(&MPU_InitStruct);
  /** Initializes and configures the Region and the memory to be protected
  */
  MPU_InitStruct.Enable = MPU_REGION_ENABLE;
  MPU_InitStruct.Number = MPU_REGION_NUMBER4;
  MPU_InitStruct.BaseAddress = 0xD0000000;
  MPU_InitStruct.Size = MPU_REGION_SIZE_32MB;
  MPU_InitStruct.SubRegionDisable = 0x0;
  MPU_InitStruct.TypeExtField = MPU_TEX_LEVEL0;
  MPU_InitStruct.AccessPermission = MPU_REGION_FULL_ACCESS;
  MPU_InitStruct.DisableExec = MPU_INSTRUCTION_ACCESS_DISABLE;
  MPU_InitStruct.IsShareable = MPU_ACCESS_NOT_SHAREABLE;
  MPU_InitStruct.IsCacheable = MPU_ACCESS_CACHEABLE;
  MPU_InitStruct.IsBufferable = MPU_ACCESS_NOT_BUFFERABLE;

  HAL_MPU_ConfigRegion(&MPU_InitStruct);
  /* Enables the MPU */
  HAL_MPU_Enable(MPU_PRIVILEGED_DEFAULT);

}
void HAL_TIM_PeriodElapsedCallback(TIM_HandleTypeDef *htim)
{
  if (htim->Instance == TIM6) {
    HAL_IncTick();
  }
}

void Error_Handler(void)
{
}

/************************ (C) COPYRIGHT STMicroelectronics *****END OF FILE****/

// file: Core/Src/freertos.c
/* USER CODE BEGIN Header */
/**
  ******************************************************************************
  * File Name          : freertos.c
  * Description        : Code for freertos applications
  ******************************************************************************
  * @attention
  *
  * <h2><center>&copy; Copyright (c) 2020 STMicroelectronics.
  * All rights reserved.</center></h2>
  *
  * This software component is licensed by ST under Ultimate Liberty license
  * SLA0044, the "License"; You may not use this file except in compliance with
  * the License. You may obtain a copy of the License at:
  *                             www.st.com/SLA0044
  *
  ******************************************************************************
  */
/* USER CODE END Header */

#include "FreeRTOS.h"
#include "task.h"
#include "main.h"

/* USER CODE BEGIN FunctionPrototypes */
extern portBASE_TYPE IdleTaskHook(void* p);
/* USER CODE END FunctionPrototypes */

/* Hook prototypes */
void vApplicationIdleHook(void);

/* USER CODE BEGIN 2 */
void vApplicationIdleHook( void )
{
   /* vApplicationIdleHook() will only be called if configUSE_IDLE_HOOK is set
   to 1 in FreeRTOSConfig.h. It will be called on each iteration of the idle
   task. It is essential that code added to this hook function never attempts
   to block in any way (for example, call xQueueReceive() with a block time
   specified, or call vTaskDelay()). If the application makes use of the
   vTaskDelete() API function (as this demo application does) then it is also
   important that vApplicationIdleHook() is permitted to return to its calling
   function, because it is the responsibility of the idle task to clean up
   memory allocated by the kernel to any task that has since been deleted. */

  vTaskSetApplicationTaskTag(NULL, IdleTaskHook);
}
/* USER CODE END 2 */

/************************ (C) COPYRIGHT STMicroelectronics *****END OF FILE****/
